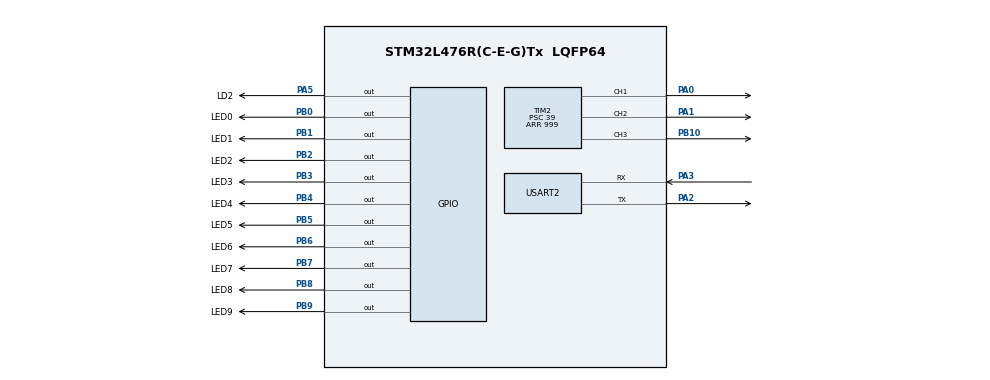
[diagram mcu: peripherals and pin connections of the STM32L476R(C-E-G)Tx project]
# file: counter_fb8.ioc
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Mcu.Family=STM32L4
Mcu.Name=STM32L476R(C-E-G)Tx
Mcu.Package=LQFP64
NVIC.PriorityGroup=NVIC_PRIORITYGROUP_4
NVIC.TIM3_IRQn=true\:8\:0\:true\:false\:true\:true\:true\:true
NVIC.TIM6_DAC_IRQn=true\:10\:0\:true\:false\:true\:true\:true\:true
PA0.Signal=S_TIM2_CH1
PA1.Signal=S_TIM2_CH2
PA13\ (JTMS-SWDIO).Mode=Serial_Wire
PA13\ (JTMS-SWDIO).Signal=SYS_JTMS-SWDIO
PA14\ (JTCK-SWCLK).Mode=Serial_Wire
PA14\ (JTCK-SWCLK).Signal=SYS_JTCK-SWCLK
PA2.Mode=Asynchronous
PA2.Signal=USART2_TX
PA3.Mode=Asynchronous
PA3.Signal=USART2_RX
PA5.GPIO_Label=LD2
PA5.Signal=GPIO_Output
PB0.GPIO_Label=LED0
PB0.Signal=GPIO_Output
PB1.GPIO_Label=LED1
PB1.Signal=GPIO_Output
PB10.Signal=S_TIM2_CH3
PB2.GPIO_Label=LED2
PB2.Signal=GPIO_Output
PB3\ (JTDO-TRACESWO).GPIO_Label=LED3
PB3\ (JTDO-TRACESWO).Signal=GPIO_Output
PB4\ (NJTRST).GPIO_Label=LED4
PB4\ (NJTRST).Signal=GPIO_Output
PB5.GPIO_Label=LED5
PB5.Signal=GPIO_Output
PB6.GPIO_Label=LED6
PB6.Signal=GPIO_Output
PB7.GPIO_Label=LED7
PB7.Signal=GPIO_Output
PB8.GPIO_Label=LED8
PB8.Signal=GPIO_Output
PB9.GPIO_Label=LED9
PB9.Signal=GPIO_Output
ProjectManager.HeapSize=0x200
ProjectManager.StackSize=0x400
ProjectManager.TargetToolchain=STM32CubeIDE
RCC.HSE_VALUE=8000000
RCC.HSI_VALUE=16000000
RCC.LSE_VALUE=32768
RCC.MSI_VALUE=4000000
RCC.VCOOutputFreq_Value=32000000
SH.S_TIM2_CH1.0=TIM2_CH1,PWM Generation1 CH1
SH.S_TIM2_CH2.0=TIM2_CH2,PWM Generation2 CH2
SH.S_TIM2_CH3.0=TIM2_CH3,PWM Generation3 CH3
TIM2.Channel-PWM\ Generation1\ CH1=TIM_CHANNEL_1
TIM2.Channel-PWM\ Generation2\ CH2=TIM_CHANNEL_2
TIM2.Channel-PWM\ Generation3\ CH3=TIM_CHANNEL_3
TIM2.Period=999
TIM2.Prescaler=39
TIM2.Pulse-PWM\ Generation1\ CH1=0
TIM2.Pulse-PWM\ Generation2\ CH2=0
TIM2.Pulse-PWM\ Generation3\ CH3=0
TIM3.Channel-Output\ Compare1\ No\ Output=TIM_CHANNEL_1
TIM3.Channel-Output\ Compare2\ No\ Output=TIM_CHANNEL_2
TIM3.Channel-Output\ Compare3\ No\ Output=TIM_CHANNEL_3
TIM3.Period=4999
TIM3.Prescaler=4999
TIM3.Pulse-Output\ Compare1\ No\ Output=1500
TIM3.Pulse-Output\ Compare2\ No\ Output=3000
TIM3.Pulse-Output\ Compare3\ No\ Output=4500
TIM6.AutoReloadPreload=TIM_AUTORELOAD_PRELOAD_DISABLE
TIM6.Period=999
TIM6.Prescaler=4999
USART2.VirtualMode-Asynchronous=VM_ASYNC
VP_TIM2_VS_ClockSourceINT.Mode=Internal
VP_TIM3_VS_ClockSourceINT.Mode=Internal
VP_TIM3_VS_no_output1.Mode=Output Compare1 No Output
VP_TIM3_VS_no_output2.Mode=Output Compare2 No Output
VP_TIM3_VS_no_output3.Mode=Output Compare3 No Output
VP_TIM6_VS_ClockSourceINT.Mode=Enable_Timer
board=custom

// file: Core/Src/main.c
/* USER CODE BEGIN Header */
/**
  ******************************************************************************
  * @file           : main.c
  * @brief          : Main program body
  ******************************************************************************
  * @attention
  *
  * Copyright (c) 2023 STMicroelectronics.
  * All rights reserved.
  *
  * This software is licensed under terms that can be found in the LICENSE file
  * in the root directory of this software component.
  * If no LICENSE file comes with this software, it is provided AS-IS.
  *
  ******************************************************************************
  */
/* USER CODE END Header */
#include "main.h"
#include "tim.h"
#include "usart.h"
#include "gpio.h"

/* USER CODE BEGIN Includes */
#include "app_main.h"
/* USER CODE END Includes */

void SystemClock_Config(void);

int main(void)
{

  /* MCU Configuration--------------------------------------------------------*/

  /* Reset of all peripherals, Initializes the Flash interface and the Systick. */
  HAL_Init();

  /* Configure the system clock */
  SystemClock_Config();

  /* Initialize all configured peripherals */
  MX_GPIO_Init();
  MX_TIM6_Init();
  MX_USART2_UART_Init();
  MX_TIM3_Init();
  MX_TIM2_Init();
  /* USER CODE BEGIN 2 */
  setup();
  /* USER CODE END 2 */

  /* Infinite loop */
  /* USER CODE BEGIN WHILE */
  while (1)
  {
	loop();
    /* USER CODE END WHILE */

  }
}

void SystemClock_Config(void)
{
  RCC_OscInitTypeDef RCC_OscInitStruct = {0};
  RCC_ClkInitTypeDef RCC_ClkInitStruct = {0};

  /** Configure the main internal regulator output voltage
  */
  if (HAL_PWREx_ControlVoltageScaling(PWR_REGULATOR_VOLTAGE_SCALE1) != HAL_OK)
  {
    Error_Handler();
  }

  /** Initializes the RCC Oscillators according to the specified parameters
  * in the RCC_OscInitTypeDef structure.
  */
  RCC_OscInitStruct.OscillatorType = RCC_OSCILLATORTYPE_MSI;
  RCC_OscInitStruct.MSIState = RCC_MSI_ON;
  RCC_OscInitStruct.MSICalibrationValue = 0;
  RCC_OscInitStruct.MSIClockRange = RCC_MSIRANGE_6;
  RCC_OscInitStruct.PLL.PLLState = RCC_PLL_NONE;
  if (HAL_RCC_OscConfig(&RCC_OscInitStruct) != HAL_OK)
  {
    Error_Handler();
  }

  /** Initializes the CPU, AHB and APB buses clocks
  */
  RCC_ClkInitStruct.ClockType = RCC_CLOCKTYPE_HCLK|RCC_CLOCKTYPE_SYSCLK
                              |RCC_CLOCKTYPE_PCLK1|RCC_CLOCKTYPE_PCLK2;
  RCC_ClkInitStruct.SYSCLKSource = RCC_SYSCLKSOURCE_MSI;
  RCC_ClkInitStruct.AHBCLKDivider = RCC_SYSCLK_DIV1;
  RCC_ClkInitStruct.APB1CLKDivider = RCC_HCLK_DIV1;
  RCC_ClkInitStruct.APB2CLKDivider = RCC_HCLK_DIV1;

  if (HAL_RCC_ClockConfig(&RCC_ClkInitStruct, FLASH_LATENCY_0) != HAL_OK)
  {
    Error_Handler();
  }
}

void Error_Handler(void)
{
  __disable_irq();
  while (1)
  {
  }
}
